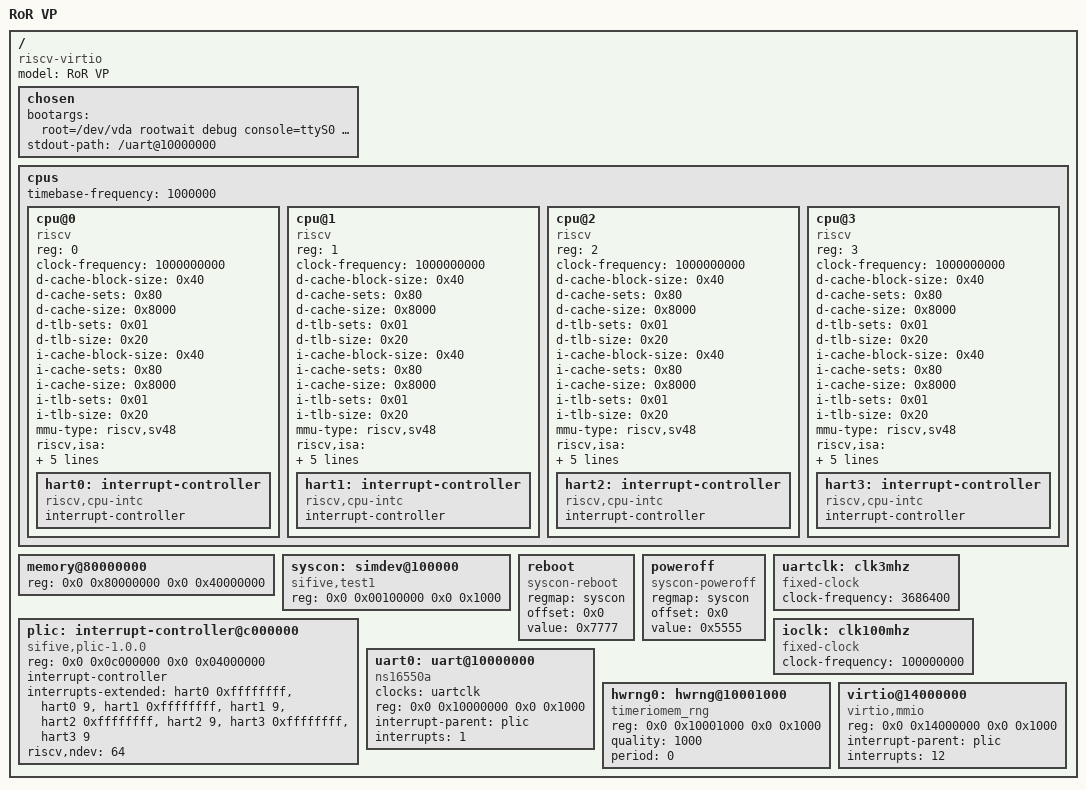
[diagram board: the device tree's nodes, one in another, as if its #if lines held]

#ifndef NRCPU
#error NRCPU undefined
#endif

/dts-v1/;

/ {
    #address-cells = <2>;
    #size-cells = <2>;
    compatible = "riscv-virtio";
    model = "RoR VP";

    chosen {
        bootargs = "root=/dev/vda rootwait debug console=ttyS0 earlycon";
        stdout-path = "/uart@10000000";

        #address-cells = <2>;
        #size-cells = <2>;
        ranges;
    };

    cpus {
        #address-cells = <1>;
        #size-cells = <0>;

        timebase-frequency = <1000000>; // 1 MHz

        cpu@0 {
            reg = <0>;
            clock-frequency = <1000000000>; // 1.4GHz
            compatible = "riscv";
            device_type = "cpu";
            d-cache-block-size = <0x40>;
			d-cache-sets = <0x80>;
			d-cache-size = <0x8000>;
			d-tlb-sets = <0x01>;
			d-tlb-size = <0x20>;
			i-cache-block-size = <0x40>;
			i-cache-sets = <0x80>;
			i-cache-size = <0x8000>;
			i-tlb-sets = <0x01>;
			i-tlb-size = <0x20>;
            mmu-type = "riscv,sv48";
            riscv,isa = "rv64imafdch_zicsr_zifencei_zba_zbb_sscofpmf";
            riscv,isa-base = "rv64i";
            riscv,isa-extensions = "i", "m", "a", "f", "d", "c", "h",
                                   "zicsr", "zifencei", "zba", "zbb",
                                   "sscofpmf";
			tlb-split;

            hart0: interrupt-controller {
                #interrupt-cells = <1>;
                compatible = "riscv,cpu-intc";
                interrupt-controller;
            };
        };
#if NRCPU > 1
         cpu@1 {
            reg = <1>;
            clock-frequency = <1000000000>; // 1.4GHz
            compatible = "riscv";
            device_type = "cpu";
            d-cache-block-size = <0x40>;
			d-cache-sets = <0x80>;
			d-cache-size = <0x8000>;
			d-tlb-sets = <0x01>;
			d-tlb-size = <0x20>;
			i-cache-block-size = <0x40>;
			i-cache-sets = <0x80>;
			i-cache-size = <0x8000>;
			i-tlb-sets = <0x01>;
			i-tlb-size = <0x20>;
            mmu-type = "riscv,sv48";
            riscv,isa = "rv64imafdch_zicsr_zifencei_zba_zbb_sscofpmf";
            riscv,isa-base = "rv64i";
            riscv,isa-extensions = "i", "m", "a", "f", "d", "c", "h",
                                   "zicsr", "zifencei", "zba", "zbb",
                                   "sscofpmf";
			tlb-split;

            hart1: interrupt-controller {
                #interrupt-cells = <1>;
                compatible = "riscv,cpu-intc";
                interrupt-controller;
            };
        };
#endif
#if NRCPU > 2
         cpu@2 {
            reg = <2>;
            clock-frequency = <1000000000>; // 1.4GHz
            compatible = "riscv";
            device_type = "cpu";
            d-cache-block-size = <0x40>;
			d-cache-sets = <0x80>;
			d-cache-size = <0x8000>;
			d-tlb-sets = <0x01>;
			d-tlb-size = <0x20>;
			i-cache-block-size = <0x40>;
			i-cache-sets = <0x80>;
			i-cache-size = <0x8000>;
			i-tlb-sets = <0x01>;
			i-tlb-size = <0x20>;
            mmu-type = "riscv,sv48";
            riscv,isa = "rv64imafdch_zicsr_zifencei_zba_zbb_sscofpmf";
            riscv,isa-base = "rv64i";
            riscv,isa-extensions = "i", "m", "a", "f", "d", "c", "h",
                                   "zicsr", "zifencei", "zba", "zbb",
                                   "sscofpmf";
			tlb-split;

            hart2: interrupt-controller {
                #interrupt-cells = <1>;
                compatible = "riscv,cpu-intc";
                interrupt-controller;
            };
        };
#endif
#if NRCPU > 3
         cpu@3 {
            reg = <3>;
            clock-frequency = <1000000000>; // 1.4GHz
            compatible = "riscv";
            device_type = "cpu";
            d-cache-block-size = <0x40>;
			d-cache-sets = <0x80>;
			d-cache-size = <0x8000>;
			d-tlb-sets = <0x01>;
			d-tlb-size = <0x20>;
			i-cache-block-size = <0x40>;
			i-cache-sets = <0x80>;
			i-cache-size = <0x8000>;
			i-tlb-sets = <0x01>;
			i-tlb-size = <0x20>;
            mmu-type = "riscv,sv48";
            riscv,isa = "rv64imafdch_zicsr_zifencei_zba_zbb_sscofpmf";
            riscv,isa-base = "rv64i";
            riscv,isa-extensions = "i", "m", "a", "f", "d", "c", "h",
                                   "zicsr", "zifencei", "zba", "zbb",
                                   "sscofpmf";
			tlb-split;

            hart3: interrupt-controller {
                #interrupt-cells = <1>;
                compatible = "riscv,cpu-intc";
                interrupt-controller;
            };
        };
#endif
    };

    memory@80000000 {
        device_type = "memory";
        reg = <0x0 0x80000000 0x0 0x40000000>;
    };

    syscon: simdev@100000 {
        compatible = "sifive,test1", "sifive,test0", "syscon";
        reg = <0x0 0x00100000 0x0 0x1000>;
    };

    reboot {
        compatible = "syscon-reboot";
        regmap = <&syscon>;
        offset = <0x0>;
        value = <0x7777>;
    };

    poweroff {
        compatible = "syscon-poweroff";
        regmap = <&syscon>;
        offset = <0x0>;
        value = <0x5555>;
    };

    plic: interrupt-controller@c000000 {
        #address-cells = <0>;
        #interrupt-cells = <1>;
        reg = <0x0 0x0c000000 0x0 0x04000000>;
        compatible = "sifive,plic-1.0.0", "riscv,plic0";
        interrupt-controller;
        interrupts-extended = <&hart0 0xffffffff>, <&hart0 9>
#if NRCPU > 1
                            , <&hart1 0xffffffff>, <&hart1 9>
#endif
#if NRCPU > 2
                            , <&hart2 0xffffffff>, <&hart2 9>
#endif
#if NRCPU > 3
                            , <&hart3 0xffffffff>, <&hart3 9>
#endif
        ;
        riscv,ndev = <64>;
    };

    uartclk: clk3mhz {
        compatible = "fixed-clock";
        #clock-cells = <0>;
        clock-frequency = <3686400>; /* 3.6864 MHz */
    };

    ioclk: clk100mhz {
        compatible = "fixed-clock";
        #clock-cells = <0>;
        clock-frequency = <100000000>;
    };

    uart0: uart@10000000 {
        compatible = "ns16550a";
        clocks = <&uartclk>;
        reg = <0x0 0x10000000 0x0 0x1000>;
        interrupt-parent = <&plic>;
        interrupts = <1>;
    };

    hwrng0: hwrng@10001000 {
        compatible = "timeriomem_rng";
        reg = <0x0 0x10001000 0x0 0x1000>;
        quality = <1000>;
        period = <0>;
    };

    virtio@14000000 {
        compatible = "virtio,mmio";
        reg = <0x0 0x14000000 0x0 0x1000>;
        interrupt-parent = <&plic>;
        interrupts = <12>;
    };
};
